VERSION ""

NS_ :

BS_:

BU_: Tester RearECU MyECU

BO_ 3221225472 VECTOR__INDEPENDENT_SIG_MSG: 0 Vector__XXX
 SG_ sig_nm_RearECU : 0|64@1+ (1,0) [0|1.8446744074E+019] "" Vector__XXX
 SG_ sig_nm_MyECU : 0|64@1+ (1,0) [0|1.8446744074E+019] "" Vector__XXX
 SG_ sig_NM_MyECU_NID : 0|8@1+ (1,0) [0|255] "" Vector__XXX
 SG_ sig_NM_MyECU_CBV : 0|8@1+ (1,0) [0|255] "" Vector__XXX
 SG_ sig_NM_MyECU_UserData_0 : 0|8@1+ (1,0) [0|255] "" Vector__XXX
 SG_ sig_NM_MyECU_UserData_1 : 0|8@1+ (1,0) [0|255] "" Vector__XXX
 SG_ sig_NM_MyECU_UserData_2 : 0|8@1+ (1,0) [0|255] "" Vector__XXX
 SG_ sig_NM_MyECU_UserData_3 : 0|8@1+ (1,0) [0|255] "" Vector__XXX
 SG_ sig_NM_MyECU_UserData_4 : 0|8@1+ (1,0) [0|255] "" Vector__XXX
 SG_ sig_NM_MyECU_UserData_5 : 0|8@1+ (1,0) [0|255] "" Vector__XXX
 SG_ sig_NM_RearECU_NID : 0|8@1+ (1,0) [0|255] "" Vector__XXX
 SG_ sig_NM_RearECU_CBV : 0|8@1+ (1,0) [0|255] "" Vector__XXX
 SG_ sig_NM_RearECU_UserData_0 : 0|8@1+ (1,0) [0|255] "" Vector__XXX
 SG_ sig_NM_RearECU_UserData_1 : 0|8@1+ (1,0) [0|255] "" Vector__XXX
 SG_ sig_NM_RearECU_UserData_2 : 0|8@1+ (1,0) [0|255] "" Vector__XXX
 SG_ sig_NM_RearECU_UserData_3 : 0|8@1+ (1,0) [0|255] "" Vector__XXX
 SG_ sig_NM_RearECU_UserData_4 : 0|8@1+ (1,0) [0|255] "" Vector__XXX
 SG_ sig_NM_RearECU_UserData_5 : 0|8@1+ (1,0) [0|255] "" Vector__XXX

BO_ 1297 msg_MyECU_Lamp: 32 MyECU
 SG_ sig_LampCnt : 7|8@0+ (1,0) [0|255] ""  RearECU

BO_ 512 msg_Transmit: 1 MyECU
 SG_ sig_RearInteriorLight : 0|1@1+ (1,0) [0|1] ""  RearECU

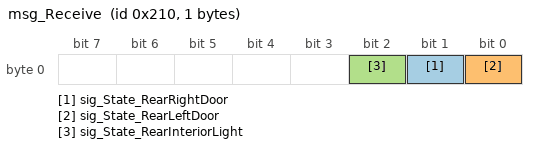
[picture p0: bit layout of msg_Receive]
BO_ 528 msg_Receive: 1 RearECU
 SG_ sig_State_RearRightDoor : 1|1@1+ (1,0) [0|1] ""  MyECU
 SG_ sig_State_RearLeftDoor : 0|1@1+ (1,0) [0|1] ""  MyECU
 SG_ sig_State_RearInteriorLight : 2|1@1+ (1,0) [0|1] ""  MyECU

BO_ 1868 msg_diag_Request_MyECU: 8 Tester
 SG_ Signal_DiagRequestMyECU : 0|64@1+ (1,0) [0|1.8446744074E+019] ""  MyECU

BO_ 1884 msg_diag_Response_MyECU: 8 MyECU
 SG_ Signal_DiagResponseMyECU : 0|64@1+ (1,0) [0|1.8446744074E+019] ""  Tester

BO_ 2015 msg_diag_RequestGlobal: 8 Tester
 SG_ Signal_DiagRequestGlobal : 0|64@1+ (1,0) [0|1.8446744074E+019] ""  MyECU

CM_ "Backup before Boot diag-only trim (had App Lamp/Transmit/Receive + unused NM sigs).";
CM_ BO_ 3221225472 "This is a message for not used signals, created by Vector CANdb++ DBC OLE DB Provider.";
CM_ BO_ 1868 "UDS physical request (ID 0x74C, Tester -> MyECU), 8 bytes classic CAN.";
CM_ BO_ 1884 "UDS physical response (ID 0x75C, MyECU -> Tester), 8 bytes classic CAN.";
CM_ BO_ 2015 "UDS functional request (ID 0x7DF, broadcast), 8 bytes classic CAN.";
BA_DEF_ BO_  "VFrameFormat" ENUM  "StandardCAN","ExtendedCAN","reserved","reserved","reserved","reserved","reserved","reserved","reserved","reserved","reserved","reserved","reserved","reserved","StandardCAN_FD","ExtendedCAN_FD";
BA_DEF_ BO_  "GenMsgCycleTime" INT 0 0;
BA_DEF_ BO_  "GenMsgSendType" ENUM  "cyclicX","spontanX","cyclicIfActiveX","spontanWithDelay","cyclicAndSpontanX","cyclicAndSpontanWithDelay","spontanWithRepetition","cyclicIfActiveAndSpontanWD","cyclicIfActiveFast","cyclicWithRepeatOnDemand";
BA_DEF_ SG_  "GenSigSendType" ENUM  "cyclicX","spontanX","cyclicIfActiveX","spontanWithDelay","cyclicAndSpontanX","cyclicAndSpontanWithDelay","spontanWithRepetition","cyclicIfActiveAndSpontanWD","cyclicIfActiveFast","cyclicWithRepeatOnDemand","none","NotUsed","NotUsed";
BA_DEF_  "Baudrate" INT 0 1000000;
BA_DEF_  "BusType" STRING ;
BA_DEF_  "Manufacturer" STRING ;
BA_DEF_ BU_  "ILUsed" ENUM  "no","yes";
BA_DEF_ BO_  "GenMsgILSupport" ENUM  "no","yes";
BA_DEF_ BO_  "DiagConnection" INT 0 65535;
BA_DEF_ BO_  "DiagRequest" ENUM  "No","Yes";
BA_DEF_ BO_  "DiagResponse" ENUM  "No","Yes";
BA_DEF_DEF_  "VFrameFormat" "ExtendedCAN_FD";
BA_DEF_DEF_  "GenMsgCycleTime" 0;
BA_DEF_DEF_  "GenMsgSendType" "cyclicX";
BA_DEF_DEF_  "GenSigSendType" "cyclicX";
BA_DEF_DEF_  "Baudrate" 500000;
BA_DEF_DEF_  "BusType" "";
BA_DEF_DEF_  "Manufacturer" "Vector";
BA_DEF_DEF_  "ILUsed" "yes";
BA_DEF_DEF_  "GenMsgILSupport" "yes";
BA_DEF_DEF_  "DiagConnection" 0;
BA_DEF_DEF_  "DiagRequest" "No";
BA_DEF_DEF_  "DiagResponse" "No";
BA_ "BusType" "CAN FD";
BA_ "Baudrate" 0;
BA_ "GenMsgCycleTime" BO_ 1297 100;
BA_ "VFrameFormat" BO_ 1297 14;
BA_ "VFrameFormat" BO_ 512 0;
BA_ "GenMsgCycleTime" BO_ 512 100;
BA_ "VFrameFormat" BO_ 528 0;
BA_ "GenMsgCycleTime" BO_ 528 100;
BA_ "VFrameFormat" BO_ 1868 0;
BA_ "GenMsgSendType" BO_ 1868 1;
BA_ "DiagConnection" BO_ 1868 57345;
BA_ "DiagRequest" BO_ 1868 1;
BA_ "VFrameFormat" BO_ 1884 0;
BA_ "GenMsgSendType" BO_ 1884 1;
BA_ "DiagConnection" BO_ 1884 57345;
BA_ "DiagResponse" BO_ 1884 1;
BA_ "VFrameFormat" BO_ 2015 0;
BA_ "GenMsgSendType" BO_ 2015 1;
BA_ "DiagConnection" BO_ 2015 57345;
BA_ "DiagRequest" BO_ 2015 1;
